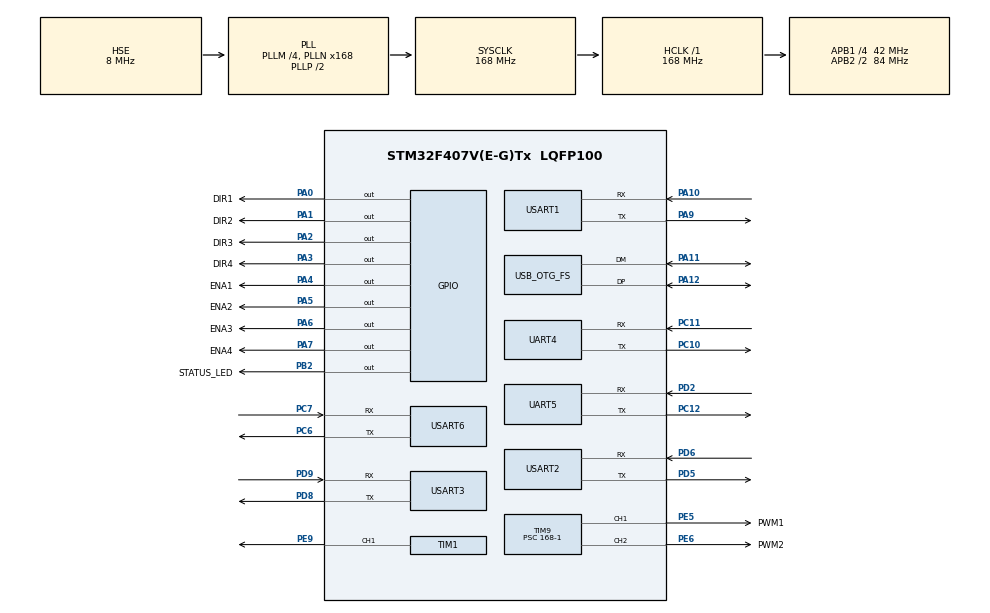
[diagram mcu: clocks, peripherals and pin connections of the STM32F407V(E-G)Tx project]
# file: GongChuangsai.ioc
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Dma.Request0=UART5_RX
Dma.Request1=UART5_TX
Dma.Request2=UART4_RX
Dma.Request3=USART6_RX
Dma.Request4=USART6_TX
Dma.Request5=USART3_RX
Dma.Request6=USART3_TX
Dma.UART4_RX.2.Direction=DMA_PERIPH_TO_MEMORY
Dma.UART4_RX.2.FIFOMode=DMA_FIFOMODE_DISABLE
Dma.UART4_RX.2.Instance=DMA1_Stream2
Dma.UART4_RX.2.MemDataAlignment=DMA_MDATAALIGN_BYTE
Dma.UART4_RX.2.MemInc=DMA_MINC_ENABLE
Dma.UART4_RX.2.Mode=DMA_CIRCULAR
Dma.UART4_RX.2.PeriphDataAlignment=DMA_PDATAALIGN_BYTE
Dma.UART4_RX.2.PeriphInc=DMA_PINC_DISABLE
Dma.UART4_RX.2.Priority=DMA_PRIORITY_HIGH
Dma.UART5_RX.0.Direction=DMA_PERIPH_TO_MEMORY
Dma.UART5_RX.0.FIFOMode=DMA_FIFOMODE_DISABLE
Dma.UART5_RX.0.Instance=DMA1_Stream0
Dma.UART5_RX.0.MemDataAlignment=DMA_MDATAALIGN_BYTE
Dma.UART5_RX.0.MemInc=DMA_MINC_ENABLE
Dma.UART5_RX.0.Mode=DMA_CIRCULAR
Dma.UART5_RX.0.PeriphDataAlignment=DMA_PDATAALIGN_BYTE
Dma.UART5_RX.0.PeriphInc=DMA_PINC_DISABLE
Dma.UART5_RX.0.Priority=DMA_PRIORITY_HIGH
Dma.UART5_TX.1.Direction=DMA_MEMORY_TO_PERIPH
Dma.UART5_TX.1.FIFOMode=DMA_FIFOMODE_DISABLE
Dma.UART5_TX.1.Instance=DMA1_Stream7
Dma.UART5_TX.1.MemDataAlignment=DMA_MDATAALIGN_BYTE
Dma.UART5_TX.1.MemInc=DMA_MINC_ENABLE
Dma.UART5_TX.1.Mode=DMA_NORMAL
Dma.UART5_TX.1.PeriphDataAlignment=DMA_PDATAALIGN_BYTE
Dma.UART5_TX.1.PeriphInc=DMA_PINC_DISABLE
Dma.UART5_TX.1.Priority=DMA_PRIORITY_MEDIUM
Dma.USART3_RX.5.Direction=DMA_PERIPH_TO_MEMORY
Dma.USART3_RX.5.FIFOMode=DMA_FIFOMODE_DISABLE
Dma.USART3_RX.5.Instance=DMA1_Stream1
Dma.USART3_RX.5.MemDataAlignment=DMA_MDATAALIGN_BYTE
Dma.USART3_RX.5.MemInc=DMA_MINC_ENABLE
Dma.USART3_RX.5.Mode=DMA_CIRCULAR
Dma.USART3_RX.5.PeriphDataAlignment=DMA_PDATAALIGN_BYTE
Dma.USART3_RX.5.PeriphInc=DMA_PINC_DISABLE
Dma.USART3_RX.5.Priority=DMA_PRIORITY_HIGH
Dma.USART3_TX.6.Direction=DMA_MEMORY_TO_PERIPH
Dma.USART3_TX.6.FIFOMode=DMA_FIFOMODE_DISABLE
Dma.USART3_TX.6.Instance=DMA1_Stream3
Dma.USART3_TX.6.MemDataAlignment=DMA_MDATAALIGN_BYTE
Dma.USART3_TX.6.MemInc=DMA_MINC_ENABLE
Dma.USART3_TX.6.Mode=DMA_NORMAL
Dma.USART3_TX.6.PeriphDataAlignment=DMA_PDATAALIGN_BYTE
Dma.USART3_TX.6.PeriphInc=DMA_PINC_DISABLE
Dma.USART3_TX.6.Priority=DMA_PRIORITY_MEDIUM
Dma.USART6_RX.3.Direction=DMA_PERIPH_TO_MEMORY
Dma.USART6_RX.3.FIFOMode=DMA_FIFOMODE_DISABLE
Dma.USART6_RX.3.Instance=DMA2_Stream1
Dma.USART6_RX.3.MemDataAlignment=DMA_MDATAALIGN_BYTE
Dma.USART6_RX.3.MemInc=DMA_MINC_ENABLE
Dma.USART6_RX.3.Mode=DMA_CIRCULAR
Dma.USART6_RX.3.PeriphDataAlignment=DMA_PDATAALIGN_BYTE
Dma.USART6_RX.3.PeriphInc=DMA_PINC_DISABLE
Dma.USART6_RX.3.Priority=DMA_PRIORITY_HIGH
Dma.USART6_TX.4.Direction=DMA_MEMORY_TO_PERIPH
Dma.USART6_TX.4.FIFOMode=DMA_FIFOMODE_DISABLE
Dma.USART6_TX.4.Instance=DMA2_Stream6
Dma.USART6_TX.4.MemDataAlignment=DMA_MDATAALIGN_BYTE
Dma.USART6_TX.4.MemInc=DMA_MINC_ENABLE
Dma.USART6_TX.4.Mode=DMA_NORMAL
Dma.USART6_TX.4.PeriphDataAlignment=DMA_PDATAALIGN_BYTE
Dma.USART6_TX.4.PeriphInc=DMA_PINC_DISABLE
Dma.USART6_TX.4.Priority=DMA_PRIORITY_MEDIUM
FREERTOS.Tasks01=defaultTask,0,512,StartDefaultTask,Default,NULL,Dynamic,NULL,NULL
FREERTOS.configTOTAL_HEAP_SIZE=16384
Mcu.Family=STM32F4
Mcu.Name=STM32F407V(E-G)Tx
Mcu.Package=LQFP100
NVIC.DMA1_Stream0_IRQn=true\:5\:0\:false\:false\:true\:true\:true\:true\:true
NVIC.DMA1_Stream1_IRQn=true\:5\:0\:false\:false\:true\:true\:true\:true\:true
NVIC.DMA1_Stream2_IRQn=true\:5\:0\:false\:false\:true\:true\:true\:true\:true
NVIC.DMA1_Stream3_IRQn=true\:5\:0\:false\:false\:true\:true\:true\:true\:true
NVIC.DMA1_Stream7_IRQn=true\:5\:0\:false\:false\:true\:true\:true\:true\:true
NVIC.DMA2_Stream1_IRQn=true\:5\:0\:false\:false\:true\:true\:true\:true\:true
NVIC.DMA2_Stream6_IRQn=true\:5\:0\:false\:false\:true\:true\:true\:true\:true
NVIC.OTG_FS_IRQn=true\:5\:0\:false\:false\:true\:true\:false\:true\:true
NVIC.PriorityGroup=NVIC_PRIORITYGROUP_4
NVIC.TIM6_DAC_IRQn=true\:15\:0\:false\:false\:true\:false\:false\:true\:true
NVIC.TimeBase=TIM6_DAC_IRQn
NVIC.TimeBaseIP=TIM6
NVIC.UART4_IRQn=true\:5\:0\:false\:false\:true\:true\:true\:true\:true
NVIC.UART5_IRQn=true\:5\:0\:false\:false\:true\:true\:true\:true\:true
NVIC.USART3_IRQn=true\:5\:0\:false\:false\:true\:true\:true\:true\:true
NVIC.USART6_IRQn=true\:5\:0\:false\:false\:true\:true\:true\:true\:true
PA0-WKUP.GPIO_Label=DIR1
PA0-WKUP.Signal=GPIO_Output
PA1.GPIO_Label=DIR2
PA1.Signal=GPIO_Output
PA10.Mode=Asynchronous
PA10.Signal=USART1_RX
PA11.Mode=Device_Only
PA11.Signal=USB_OTG_FS_DM
PA12.Mode=Device_Only
PA12.Signal=USB_OTG_FS_DP
PA13.Mode=Serial_Wire
PA13.Signal=SYS_JTMS-SWDIO
PA14.Mode=Serial_Wire
PA14.Signal=SYS_JTCK-SWCLK
PA2.GPIO_Label=DIR3
PA2.Signal=GPIO_Output
PA3.GPIO_Label=DIR4
PA3.Signal=GPIO_Output
PA4.GPIO_Label=ENA1
PA4.PinState=GPIO_PIN_RESET
PA4.Signal=GPIO_Output
PA5.GPIO_Label=ENA2
PA5.PinState=GPIO_PIN_RESET
PA5.Signal=GPIO_Output
PA6.GPIO_Label=ENA3
PA6.PinState=GPIO_PIN_RESET
PA6.Signal=GPIO_Output
PA7.GPIO_Label=ENA4
PA7.PinState=GPIO_PIN_RESET
PA7.Signal=GPIO_Output
PA9.Mode=Asynchronous
PA9.Signal=USART1_TX
PB2.GPIO_Label=STATUS_LED
PB2.Signal=GPIO_Output
PC10.Mode=Asynchronous
PC10.Signal=UART4_TX
PC11.Mode=Asynchronous
PC11.Signal=UART4_RX
PC12.Mode=Asynchronous
PC12.Signal=UART5_TX
PC6.Mode=Asynchronous
PC6.Signal=USART6_TX
PC7.Mode=Asynchronous
PC7.Signal=USART6_RX
PD2.Mode=Asynchronous
PD2.Signal=UART5_RX
PD5.Mode=Asynchronous
PD5.Signal=USART2_TX
PD6.Mode=Asynchronous
PD6.Signal=USART2_RX
PD8.Mode=Asynchronous
PD8.Signal=USART3_TX
PD9.Mode=Asynchronous
PD9.Signal=USART3_RX
PE5.GPIO_Label=PWM1
PE5.Signal=S_TIM9_CH1
PE6.GPIO_Label=PWM2
PE6.Signal=S_TIM9_CH2
PE9.Signal=S_TIM1_CH1
PH0-OSC_IN.Mode=HSE-External-Oscillator
PH0-OSC_IN.Signal=RCC_OSC_IN
PH1-OSC_OUT.Mode=HSE-External-Oscillator
PH1-OSC_OUT.Signal=RCC_OSC_OUT
ProjectManager.HeapSize=0x200
ProjectManager.StackSize=0x400
ProjectManager.TargetToolchain=CMake
RCC.48MHZClocksFreq_Value=48000000
RCC.AHBFreq_Value=168000000
RCC.APB1CLKDivider=RCC_HCLK_DIV4
RCC.APB1Freq_Value=42000000
RCC.APB1TimFreq_Value=84000000
RCC.APB2CLKDivider=RCC_HCLK_DIV2
RCC.APB2Freq_Value=84000000
RCC.APB2TimFreq_Value=168000000
RCC.CortexFreq_Value=168000000
RCC.HCLKFreq_Value=168000000
RCC.HSE_VALUE=8000000
RCC.HSI_VALUE=16000000
RCC.LSE_VALUE=32768
RCC.PLLM=4
RCC.PLLN=168
RCC.PLLQ=7
RCC.SYSCLKFreq_VALUE=168000000
RCC.SYSCLKSource=RCC_SYSCLKSOURCE_PLLCLK
RCC.VCOOutputFreq_Value=336000000
SH.S_TIM1_CH1.0=TIM1_CH1,PWM Generation1 CH1
SH.S_TIM9_CH1.0=TIM9_CH1,PWM Generation1 CH1
SH.S_TIM9_CH2.0=TIM9_CH2,PWM Generation2 CH2
TIM1.Channel-PWM\ Generation1\ CH1=TIM_CHANNEL_1
TIM1.Period=499
TIM1.Prescaler=168-1
TIM1.Pulse-PWM\ Generation1\ CH1=250
TIM9.AutoReloadPreload=TIM_AUTORELOAD_PRELOAD_ENABLE
TIM9.Channel-PWM\ Generation1\ CH1=TIM_CHANNEL_1
TIM9.Channel-PWM\ Generation2\ CH2=TIM_CHANNEL_2
TIM9.Period=19999
TIM9.Prescaler=168-1
TIM9.Pulse-PWM\ Generation1\ CH1=1500
TIM9.Pulse-PWM\ Generation2\ CH2=250
UART4.VirtualMode=Asynchronous
UART5.VirtualMode=Asynchronous
USART1.VirtualMode=VM_ASYNC
USART2.VirtualMode=VM_ASYNC
USART3.VirtualMode=VM_ASYNC
USART6.VirtualMode=VM_ASYNC
USB_DEVICE.CLASS_NAME_FS=CDC
USB_DEVICE.VirtualMode-CDC_FS=Cdc
USB_DEVICE.VirtualModeFS=Cdc_FS
USB_OTG_FS.VirtualMode=Device_Only
VP_FREERTOS_VS_CMSIS_V1.Mode=CMSIS_V1
VP_SYS_VS_tim6.Mode=TIM6
VP_USB_DEVICE_VS_USB_DEVICE_CDC_FS.Mode=CDC_FS
board=custom

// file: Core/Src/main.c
/* USER CODE BEGIN Header */
/**
  ******************************************************************************
  * @file           : main.c
  * @brief          : Main program body
  ******************************************************************************
  * @attention
  *
  * Copyright (c) 2026 STMicroelectronics.
  * All rights reserved.
  *
  * This software is licensed under terms that can be found in the LICENSE file
  * in the root directory of this software component.
  * If no LICENSE file comes with this software, it is provided AS-IS.
  *
  ******************************************************************************
  */
/* USER CODE END Header */
#include "main.h"
#include "cmsis_os.h"
#include "dma.h"
#include "tim.h"
#include "usart.h"
#include "usb_device.h"
#include "gpio.h"

void SystemClock_Config(void);
void MX_FREERTOS_Init(void);

int main(void)
{

  /* MCU Configuration--------------------------------------------------------*/

  /* Reset of all peripherals, Initializes the Flash interface and the Systick. */
    HAL_Init();

  /* Configure the system clock */
  SystemClock_Config();

  /* Initialize all configured peripherals */
  MX_GPIO_Init();
  MX_DMA_Init();
  MX_TIM9_Init();
  MX_UART5_Init();
  MX_USART2_UART_Init();
  MX_USART3_UART_Init();
  MX_USART6_UART_Init();
  MX_TIM1_Init();
  MX_USART1_UART_Init();
  MX_UART4_Init();

  /* Call init function for freertos objects (in cmsis_os2.c) */
  MX_FREERTOS_Init();

  /* Start scheduler */
  osKernelStart();

  /* We should never get here as control is now taken by the scheduler */

  /* Infinite loop */
  while (1)
  {

  }
}

void SystemClock_Config(void)
{
  RCC_OscInitTypeDef RCC_OscInitStruct = {0};
  RCC_ClkInitTypeDef RCC_ClkInitStruct = {0};

  /** Configure the main internal regulator output voltage
  */
  __HAL_RCC_PWR_CLK_ENABLE();
  __HAL_PWR_VOLTAGESCALING_CONFIG(PWR_REGULATOR_VOLTAGE_SCALE1);

  /** Initializes the RCC Oscillators according to the specified parameters
  * in the RCC_OscInitTypeDef structure.
  */
  RCC_OscInitStruct.OscillatorType = RCC_OSCILLATORTYPE_HSE;
  RCC_OscInitStruct.HSEState = RCC_HSE_ON;
  RCC_OscInitStruct.PLL.PLLState = RCC_PLL_ON;
  RCC_OscInitStruct.PLL.PLLSource = RCC_PLLSOURCE_HSE;
  RCC_OscInitStruct.PLL.PLLM = 4;
  RCC_OscInitStruct.PLL.PLLN = 168;
  RCC_OscInitStruct.PLL.PLLP = RCC_PLLP_DIV2;
  RCC_OscInitStruct.PLL.PLLQ = 7;
  if (HAL_RCC_OscConfig(&RCC_OscInitStruct) != HAL_OK)
  {
    Error_Handler();
  }

  /** Initializes the CPU, AHB and APB buses clocks
  */
  RCC_ClkInitStruct.ClockType = RCC_CLOCKTYPE_HCLK|RCC_CLOCKTYPE_SYSCLK
                              |RCC_CLOCKTYPE_PCLK1|RCC_CLOCKTYPE_PCLK2;
  RCC_ClkInitStruct.SYSCLKSource = RCC_SYSCLKSOURCE_PLLCLK;
  RCC_ClkInitStruct.AHBCLKDivider = RCC_SYSCLK_DIV1;
  RCC_ClkInitStruct.APB1CLKDivider = RCC_HCLK_DIV4;
  RCC_ClkInitStruct.APB2CLKDivider = RCC_HCLK_DIV2;

  if (HAL_RCC_ClockConfig(&RCC_ClkInitStruct, FLASH_LATENCY_5) != HAL_OK)
  {
    Error_Handler();
  }
}

void HAL_TIM_PeriodElapsedCallback(TIM_HandleTypeDef *htim)
{
  if (htim->Instance == TIM6)
  {
    HAL_IncTick();
  }
}

void Error_Handler(void)
{
  __disable_irq();
  while (1)
  {
  }
}

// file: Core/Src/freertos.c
/* USER CODE BEGIN Header */
/**
  ******************************************************************************
  * File Name          : freertos.c
  * Description        : Code for freertos applications
  ******************************************************************************
  * @attention
  *
  * Copyright (c) 2026 STMicroelectronics.
  * All rights reserved.
  *
  * This software is licensed under terms that can be found in the LICENSE file
  * in the root directory of this software component.
  * If no LICENSE file comes with this software, it is provided AS-IS.
  *
  ******************************************************************************
  */
/* USER CODE END Header */

#include "FreeRTOS.h"
#include "task.h"
#include "main.h"
#include "cmsis_os.h"

/* USER CODE BEGIN Includes */
#include "robot_task.h"
/* USER CODE END Includes */

osThreadId defaultTaskHandle;

void StartDefaultTask(void const * argument);

extern void MX_USB_DEVICE_Init(void);
void MX_FREERTOS_Init(void); /* (MISRA C 2004 rule 8.1) */

/* GetIdleTaskMemory prototype (linked to static allocation support) */
void vApplicationGetIdleTaskMemory( StaticTask_t **ppxIdleTaskTCBBuffer, StackType_t **ppxIdleTaskStackBuffer, uint32_t *pulIdleTaskStackSize );

/* USER CODE BEGIN GET_IDLE_TASK_MEMORY */
static StaticTask_t xIdleTaskTCBBuffer;
static StackType_t xIdleStack[configMINIMAL_STACK_SIZE];

void vApplicationGetIdleTaskMemory( StaticTask_t **ppxIdleTaskTCBBuffer, StackType_t **ppxIdleTaskStackBuffer, uint32_t *pulIdleTaskStackSize )
{
  *ppxIdleTaskTCBBuffer = &xIdleTaskTCBBuffer;
  *ppxIdleTaskStackBuffer = &xIdleStack[0];
  *pulIdleTaskStackSize = configMINIMAL_STACK_SIZE;
  /* place for user code */
}
/* USER CODE END GET_IDLE_TASK_MEMORY */

void MX_FREERTOS_Init(void) {

  /* Create the thread(s) */
  /* definition and creation of defaultTask */
  osThreadDef(defaultTask, StartDefaultTask, osPriorityNormal, 0, 512);
  defaultTaskHandle = osThreadCreate(osThread(defaultTask), NULL);

  /* USER CODE BEGIN RTOS_THREADS */
  if (defaultTaskHandle == NULL || !RobotTaskInit())
  {
    Error_Handler();
  }
  /* USER CODE END RTOS_THREADS */

}

void StartDefaultTask(void const * argument)
{
  /* init code for USB_DEVICE */
  MX_USB_DEVICE_Init();
  /* USER CODE BEGIN StartDefaultTask */
  /* Infinite loop */
  for(;;)
  {
    /* Report progress after this cycle's application work has completed. */
    RobotTaskHeartbeat();
    osDelay(1);
  }
  /* USER CODE END StartDefaultTask */
}
